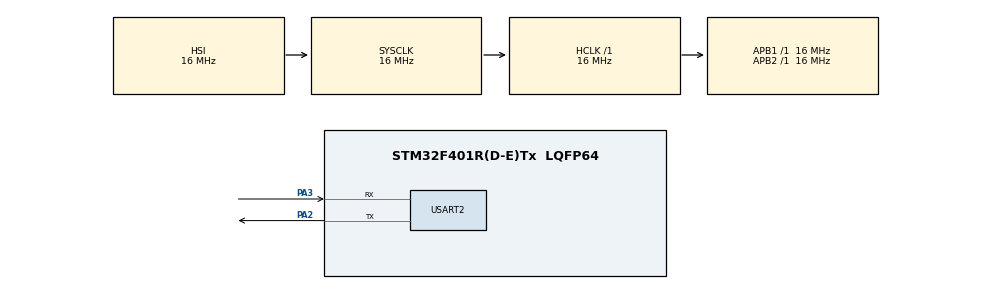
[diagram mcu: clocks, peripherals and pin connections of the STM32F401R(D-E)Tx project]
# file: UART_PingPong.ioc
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Mcu.Family=STM32F4
Mcu.Name=STM32F401R(D-E)Tx
Mcu.Package=LQFP64
NVIC.PriorityGroup=NVIC_PRIORITYGROUP_4
NVIC.USART2_IRQn=true\:0\:0\:false\:false\:true\:true\:true\:true
PA2.Mode=Asynchronous
PA2.Signal=USART2_TX
PA3.Mode=Asynchronous
PA3.Signal=USART2_RX
ProjectManager.HeapSize=0x200
ProjectManager.StackSize=0x400
ProjectManager.TargetToolchain=STM32CubeIDE
RCC.AHBFreq_Value=16000000
RCC.APB1Freq_Value=16000000
RCC.APB2Freq_Value=16000000
RCC.CortexFreq_Value=16000000
RCC.HSE_VALUE=25000000
RCC.HSI_VALUE=16000000
RCC.LSE_VALUE=32768
RCC.SYSCLKFreq_VALUE=16000000
RCC.VCOOutputFreq_Value=192000000
USART2.VirtualMode=VM_ASYNC
board=custom

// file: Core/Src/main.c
/* USER CODE BEGIN Header */
/**
  ******************************************************************************
  * @file           : main.c
  * @brief          : Main program body
  ******************************************************************************
  */
/* USER CODE END Header */

#include "main.h"
#include <string.h> // For strncmp

UART_HandleTypeDef huart2;
uint8_t rxData[10];
uint8_t txData[] = "PONG\r\n";

void SystemClock_Config(void);
static void MX_GPIO_Init(void);
static void MX_USART2_UART_Init(void);

/* USER CODE BEGIN 0 */
void HAL_UART_RxCpltCallback(UART_HandleTypeDef *huart)
{
  if (huart->Instance == USART2)
  {
    if (strncmp((char*)rxData, "PING", 4) == 0)
    {
      HAL_UART_Transmit(&huart2, txData, sizeof(txData)-1, HAL_MAX_DELAY);
    }

    HAL_UART_Receive_IT(&huart2, rxData, sizeof(rxData)); // Restart the reception
  }
}
/* USER CODE END 0 */

int main(void)
{
  HAL_Init();
  SystemClock_Config();
  MX_GPIO_Init();
  MX_USART2_UART_Init();

  // Start UART interrupt reception
  HAL_UART_Receive_IT(&huart2, rxData, sizeof(rxData));

  while (1)
  {
    // Main loop is empty; everything happens in interrupts
  }
}

void SystemClock_Config(void)
{
  RCC_OscInitTypeDef RCC_OscInitStruct = {0};
  RCC_ClkInitTypeDef RCC_ClkInitStruct = {0};

  __HAL_RCC_PWR_CLK_ENABLE();
  __HAL_PWR_VOLTAGESCALING_CONFIG(PWR_REGULATOR_VOLTAGE_SCALE2);
  RCC_OscInitStruct.OscillatorType = RCC_OSCILLATORTYPE_HSI;
  RCC_OscInitStruct.HSIState = RCC_HSI_ON;
  RCC_OscInitStruct.HSICalibrationValue = RCC_HSICALIBRATION_DEFAULT;
  RCC_OscInitStruct.PLL.PLLState = RCC_PLL_NONE;
  HAL_RCC_OscConfig(&RCC_OscInitStruct);
  RCC_ClkInitStruct.ClockType = RCC_CLOCKTYPE_HCLK|RCC_CLOCKTYPE_SYSCLK
                              |RCC_CLOCKTYPE_PCLK1|RCC_CLOCKTYPE_PCLK2;
  RCC_ClkInitStruct.SYSCLKSource = RCC_SYSCLKSOURCE_HSI;
  RCC_ClkInitStruct.AHBCLKDivider = RCC_SYSCLK_DIV1;
  RCC_ClkInitStruct.APB1CLKDivider = RCC_HCLK_DIV1;
  RCC_ClkInitStruct.APB2CLKDivider = RCC_HCLK_DIV1;
  HAL_RCC_ClockConfig(&RCC_ClkInitStruct, FLASH_LATENCY_0);
}

static void MX_USART2_UART_Init(void)
{
  huart2.Instance = USART2;
  huart2.Init.BaudRate = 115200;
  huart2.Init.WordLength = UART_WORDLENGTH_8B;
  huart2.Init.StopBits = UART_STOPBITS_1;
  huart2.Init.Parity = UART_PARITY_NONE;
  huart2.Init.Mode = UART_MODE_TX_RX;
  huart2.Init.HwFlowCtl = UART_HWCONTROL_NONE;
  huart2.Init.OverSampling = UART_OVERSAMPLING_16;
  HAL_UART_Init(&huart2);
}

static void MX_GPIO_Init(void)
{
  __HAL_RCC_GPIOA_CLK_ENABLE();
}

/**
  * @brief Error Handler
  * @retval None
  */
void Error_Handler(void)
{
  __disable_irq();
  while (1) {}
}
